# psoc6_01 register map
Vendor: Infineon Technologies; Series: PSOC6_01; File version: 1.0
CPU: CM4 r0p1, little endian, MPU, FPU, VTOR, 3 interrupt priority bits
Registers are 32-bit, read-write, reset 0x0 unless marked. A register's access mark holds for its fields unless they carry their own. Offsets are from the block's base; [hi:lo] are bit positions; lines under a group give offsets from that group.

## BLE (part 2 of 5) — Bluetooth Low Energy Subsystem
Base 0x403C0000
0x1000 BLELL group — Bluetooth Low Energy Link Layer
  0x00 COMMAND_REGISTER wo — Instruction Register
    [7:0] COMMAND
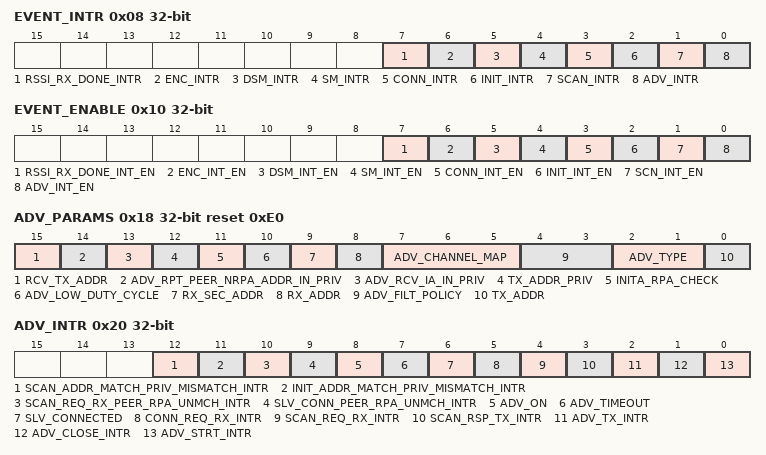
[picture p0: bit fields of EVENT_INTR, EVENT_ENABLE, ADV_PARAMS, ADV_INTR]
  0x08 EVENT_INTR — Event(Interrupt) status and Clear register
    [7] RSSI_RX_DONE_INTR ro — RSSI RX done interrupt.
    [6] ENC_INTR ro — Encryption module interrupt. This interrupt id deprecated and should not be used
    [5] DSM_INTR — Read: Deep sleep mode exit interrupt. This bit is set, when link layer hardware exits from deep sleep mode. Write: Clear deep sleep mode exit interrupt. Write to the register with this bit set to 1, clears the interrupt source.
    [4] SM_INTR — Read: Sleep-mode-exit interrupt. This bit is set, when link layer hardware exits from sleep mode. Write: Clear sleep-mode-exit interrupt. Write to the register with this bit set to 1, clears the interrupt source. This interrupt is deprecated and should not be used.
    [3] CONN_INTR ro — Connection interrupt. If bit is set to 1, it indicates an event occurred in the connection operation. This interrupt is aggregation of interrupts for all the connections. The source of the event for the specific connection, needs to be read from the CONN_INTR register specific to the connection. This bit is cleared, when firmware clears ALL interrupts by writing to the CONN_INTR register.
    [2] INIT_INTR ro — Initiator interrupt. If bit is set to 1, it indicates an event occurred in the initiating procedure. The source of the event needs to be read from the INIT_INTR register. This bit is cleared, when firmware clears ALL interrupts by writing to the INIT_INTR register.
    [1] SCAN_INTR ro — Scanner interrupt. If bit is set to 1, it indicates an event occurred in the scanning procedure. The source of the event needs to be read from the SCAN_INTR register. This bit is cleared, when firmware clears ALL interrupts by writing to the SCAN_INTR register.
    [0] ADV_INTR ro — Advertiser interrupt. If bit is set to 1, it indicates an event occurred in the advertising procedure. The source of the event needs to be read from the ADV_INTR register. This bit is cleared, when firmware clears ALL interrupts by writing to the ADV_INTR register.
  0x10 EVENT_ENABLE — Event indications enable.
    [7] RSSI_RX_DONE_INT_EN — RSSI Rx interrupt enable. 1 - Enable RSSI Rx done interrupt to firmware. 0 - Disable RSSI Rx done interrupt to firmware.
    [6] ENC_INT_EN — Encryption module interrupt enable. 1 - Enable encryption module interrupt to firmware. 0 - disable encryption module interrupt to firmware. This interrupt is deprecated and should not be used
    [5] DSM_INT_EN — Deep Sleep-mode-exit interrupt enable. 1 - enable deep sleep mode exit event to interrupt the firmware. 0 - disable deep sleep mode exit interrupt to firmware.
    [4] SM_INT_EN — Sleep-mode-exit interrupt enable. 1 - enable sleep mode exit event to interrupt the firmware. 0 - disable sleep mode exit interrupt to firmware. This interrupt is deprecated and should not be used.
    [3] CONN_INT_EN — Connection interrupt enable. 1 - enable connection procedure to interrupt the firmware. 0 - disable connection procedure interrupt to firmware.
    [2] INIT_INT_EN — Initiator interrupt enable. 1 - enable initiator procedure to interrupt the firmware. 0 - disable initiator procedure interrupt to firmware.
    [1] SCN_INT_EN — Scanner interrupt enable. 1 - enable scan procedure to interrupt the firmware. 0 - disable scan procedure interrupt to firmware.
    [0] ADV_INT_EN — Advertiser interrupt enable. 1 - enable advertiser procedure to interrupt the firmware. 0 - disable advertiser procedure interrupt to firmware.
  0x18 ADV_PARAMS reset 0xE0 — Advertising parameters register.
    [15] RCV_TX_ADDR ro — Transmit address field of the received packet extracted from the receive packet. This field is used by firmware to report peer_addr_type parameter in the connection complete event.
    [14] ADV_RPT_PEER_NRPA_ADDR_IN_PRIV — Advertiser behavior when a peer Non Resolvable Private Address is received in privacy mode. This bit is valid only if PRIV_1_2 and PRIV_1_2_ADV are set. This is applicable when whitelist is disabled. 1 - Only report the packets with peer NRPA address in privacy mode 0 - Respond to packets with peer NRPA address in privacy mode
    [13] ADV_RCV_IA_IN_PRIV — Advertiser behavior when a peer Identity address is received in privacy mode. This bit is valid only if PRIV_1_2 and PRIV_1_2_ADV are set. 1 - Accept packets with peer identity address not in the Resolving list in privacy mode 0 - Reject packets with peer identity address not in the Resolving list in privacy mode
    [12] TX_ADDR_PRIV — Device own address type subtype when Address type is random. This bit is valid only if PRIV_1_2 and PRIV_1_2_ADV are set. 1 - Random Address type is private. 0 - Random Address type is static.
    [11] INITA_RPA_CHECK — This bit field is used to specify the Advertiser behavior on receiving the same INITA in the connect_req as in the ADV_DIRECT_IND packet it sent. This bit is valid only if PRIV_1_2 and PRIV_1_2_ADV are set. 0 - Accept the connect_req packet 1 - Reject the connect_req packet
    [10] ADV_LOW_DUTY_CYCLE — This bit field is used to specify to the Controller the Low Duty Cycle connectable directed advertising variant being used. 1 - Low Duty Cycle Connectable Directed Advertising. 0 - High Duty Cycle Connectable Directed Advertising.
    [9] RX_SEC_ADDR — Peer secondary addresses type. This is the Direct_Address_type field programmed, only if ADV_DIRECT_IND type is sent. This address type corresponds to the PEER_SERC_ADDR register. Valid only if PRIV_1_2_ADV is set. 1 - Rx secondary addr type is random. 0 - Rx secondary addr type is public
    [8] RX_ADDR — Peer addresses type. This is the Direct_Address_type field programmed, only if ADV_DIRECT_IND type is sent. 1 - Rx addr type is random. 0 - Rx addr type is public
    [7:5] ADV_CHANNEL_MAP — Advertising channel map indicates the advertising channels used for advertising. By setting the bit, corresponding channel is enabled for use. Atleast one channel bit should be set. 7 - enable channel 39. 6 - enable channel 38. 5 - enable channel 37.
    [4:3] ADV_FILT_POLICY — Advertising filter policy. The set of devices that the advertising procedure uses for device filtering is called the White List. 0x0 - Allow scan request from any device, allow connect request from any device. 0x1 - Allow scan request from devices in white list only, allow connect request from any device. 0x2 - Allow scan request from any device, allow connect request from devices in white list only. 0x3 - Allow scan request from devices in white list only, allow connect request from devices in white list only.
    [2:1] ADV_TYPE — The Advertising type is used to determine the packet type that is used for advertising when advertising is enabled. 0x0 - Connectable undirected advertising. (adv_ind) 0x1 - Connectable directed advertising (adv_direct_ind). 0x2 - Discoverable undirected advertising (adv_discover_ind) 0x3 - Non connectable undirected advertising (adv_nonconn_ind).
    [0] TX_ADDR — Device own address type. 1 - Address type is random. 0 - Address type is public.
  0x1C ADV_INTERVAL_TIMEOUT reset 0x20 — Advertising interval register.
    [14:0] ADV_INTERVAL — Range: 0x0020 to 0x4000 (For ADV_IND) 0x00A0 to 0x4000 (For ADV_SCAN_IND and NONCONN_IND) Invalid for ADV_DIRECT_IND Time = N * 0.625 msec Time Range: 20 ms to 10.24 sec. For directed advertising, firmware programs the default value of 1.28 seconds. In MMMS mode, this register is used as ADV_NI_TIMER when the ADV_NI_VALID is set by firmware
  0x20 ADV_INTR — Advertising interrupt status and Clear register
    [12] SCAN_ADDR_MATCH_PRIV_MISMATCH_INTR — If this bit is set it indicates that an Identity address is received from an initiator and matches an entry in the resolving list, but peer IRK is set and hence a corresponding RPA is expected from the initiator Write to the register with this bit set to 1, clears the interrupt source. This bit is valid only if PRIV_1_2 and PRIV_1_2_ADV are set.
    [11] INIT_ADDR_MATCH_PRIV_MISMATCH_INTR — If this bit is set it indicates that an Identity address is received from a Scanner and matches an entry in the resolving list, but peer IRK is set and hence a corresponding RPA is expected from the Scanner Write to the register with this bit set to 1, clears the interrupt source. This bit is valid only if PRIV_1_2 and PRIV_1_2_ADV are set.
    [10] SCAN_REQ_RX_PEER_RPA_UNMCH_INTR — If this bit is set it indicates scan request packet received, but the peer device Resolvable Private Address is not resolved/ ID or NRPA are not matched yet. Write to the register with this bit set to 1, clears the interrupt source. This bit is valid only if PRIV_1_2 and PRIV_1_2_ADV are set.
    [9] SLV_CONN_PEER_RPA_UNMCH_INTR — If this bit is set it indicates that connection is created as slave, but the peer device Resolvable Private Address is not resolved/ ID or NRPA are not matched yet. If the address is not resolved prior to connection establishment, the connection will be terminated. Write to the register with this bit set to 1, clears the interrupt source. This bit is valid only if PRIV_1_2 and PRIV_1_2_ADV are set.
    [8] ADV_ON ro — Advertiser procedure is ON in hardware. Indicates that advertiser procedure is ON in hardware. 1 - ON 0 - OFF
    [7] ADV_TIMEOUT — If this bit is set it indicates that the directed advertising event has timed out after 1.28 seconds. Applicable in adv_direct_ind advertising. Write to the register with this bit set to 1, clears the interrupt source.
    [6] SLV_CONNECTED — If this bit is set it indicates that connection is created as slave. Write to the register with this bit set to 1, clears the interrupt source. Note: On a slave connection creation, the link layer cannot enter deepsleep mode in the same slot . It can enter deepsleep mode only in the subsequent slots.
    [5] CONN_REQ_RX_INTR — If this bit is set it indicates connect request packet is received. Write to the register with this bit set to 1, clears the interrupt source.
    [4] SCAN_REQ_RX_INTR — If this bit is set it indicates scan request packet received. Write to the register with this bit set to 1, clears the interrupt source.
    [3] SCAN_RSP_TX_INTR — If this bit is set it indicates scan response packet transmitted in response to previous scan request packet received. Write to the register with this bit set to 1, clears the interrupt source.
    [2] ADV_TX_INTR — If this bit is set it indicates ADV packet is transmitted. Write to the register with this bit set to 1, clears the interrupt source.
    [1] ADV_CLOSE_INTR — If this bit is set it indicates current advertising event is closed. Write to the register with this bit set to 1, clears the interrupt source.
    [0] ADV_STRT_INTR — If this bit is set it indicates a new advertising event started after interval expiry. Write to the register with this bit set to 1, clears the interrupt source.
  0x24 ADV_NEXT_INSTANT ro — Advertising next instant.
    [15:0] ADV_NEXT_INSTANT — Shows the next start of advertising event with reference to the internal reference clock.
  0x28 SCAN_INTERVAL reset 0x10
    [15:0] SCAN_INTERVAL — Scan interval register. Interval between two consecutive scanning events. Firmware sets the scanning interval value to this register before issuing start scan command. Range: 0x0004 to 0x4000 Default: 0x0010 (10 ms) Time = N * 0.625 msec Time Range: 2.5 msec to 10.24 sec. In MMMS mode, this register is used as SCAN_NI_TIMER when the SCAN_NI_VALID is set by firmware
  0x2C SCAN_WINDOW reset 0x10
    [15:0] SCAN_WINDOW — Duration of scan in a scanning event, which should be less than or equal to scan interval value. Firmware sets the scan window value to this register before issuing start scan command. Range: 0x0004 to 0x4000 Default: 0x0010 (10 ms) Time = N * 0.625 msec Time Range: 2.5 msec to 10.24 sec. (To prevent ADV RX - SCAN REQ TX - SCAN RSP RX spilling over across the scan window, when not in continuous scan, the scan window must be 2 slots less that the scan interval.
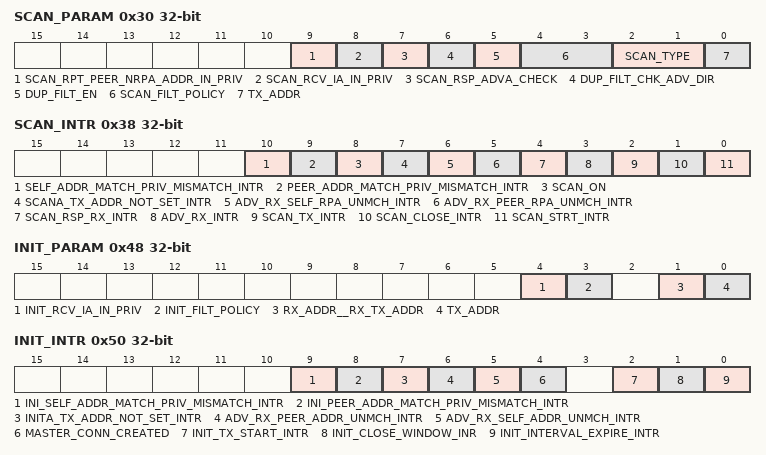
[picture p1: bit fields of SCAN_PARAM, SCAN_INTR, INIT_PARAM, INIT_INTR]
  0x30 SCAN_PARAM — Scanning parameters register
    [9] SCAN_RPT_PEER_NRPA_ADDR_IN_PRIV — Scanner behavior when a peer Non Resolvable Private Address is received in privacy mode. This bit is valid only if PRIV_1_2 and PRIV_1_2_SCAN are set. This is applicable when whitelist is disabled. 1 - Only report packets with peer NRPA address in privacy mode 0 - Respond packets with peer NRPA address in privacy mode
    [8] SCAN_RCV_IA_IN_PRIV — Scanner behavior when a peer Identity address is received in privacy mode. This bit is valid only if PRIV_1_2 and PRIV_1_2_SCAN are set. 1 - Accept packets with peer identity address not in the Resolving list in privacy mode 0 - Reject packets with peer identity address not in the Resolving list in privacy mode
    [7] SCAN_RSP_ADVA_CHECK — This bit field is used to specify the Scanner behavior with respect to ADVA while receiving a SCAN_RSP packet. This bit is valid only if PRIV_1_2 and PRIV_1_2_SCAN are set. 0 - The ADVA in SCAN_RSP packets are not verified 1 - The ADVA in SCAN_RSP packets are verified against ADVA received in ADV packet . If it fails, then abort the packet.
    [6] DUP_FILT_CHK_ADV_DIR — This bit field is used to specify the Scanner duplicate filter behavior for ADV_DIRECT_IND packet when duplicate DUP_FILT_EN is set. This bit is valid only if PRIV_1_2 and PRIV_1_2_SCAN are set. 0 - Do not filter ADV_DIRECT_IND duplicate packets. 1 - Filter ADV_DIRECT_IND duplicate packets
    [5] DUP_FILT_EN — Filter duplicate packets. 1- Duplicate filtering enabled. 0- Duplicate filtering not enabled. This field is derived from the LE_set_scan_enable command.
    [4:3] SCAN_FILT_POLICY — The scanner filter policy determines how the scanner processes advertising packets. 0x00 - Accept advertising packets from any device. 0x01 - Accept advertising packets from only devices in the whitelist. In the above 2 policies, the directed advertising packets which are not addressed to this device are ignored. 0x10 - Accept all undirected advertising packets and directed advertising packet addressed to this device. 0x11 - Accept undirected advertising packets from devices in the whitelist and directed advertising packet addressed to this device In the above 2 policies, the directed advertising packets where the initiator address is a resolvable private address are accepted. The above 2 policies are extended scanner filter policies.
    [2:1] SCAN_TYPE — 0x00 - passive scanning.(default) 0x01 - active scanning. 0x10 - RFU 0x11 - RFU
    [0] TX_ADDR — Device's own address type. 1 - addr type is random. 0 - addr type is public.
  0x38 SCAN_INTR — Scan interrupt status and Clear register
    [10] SELF_ADDR_MATCH_PRIV_MISMATCH_INTR — If this bit is set it indicates that the self Identity address is received from an initiator and matches, but self IRK is set and hence a corresponding RPA is expected from the initiator Write to the register with this bit set to 1, clears the interrupt source. This bit is valid only if PRIV_1_2 and PRIV_1_2_SCAN are set.
    [9] PEER_ADDR_MATCH_PRIV_MISMATCH_INTR — If this bit is set it indicates that an Identity address is received from an initiator and matches an entry in the resolving list, but peer IRK is set and hence a corresponding RPA is expected from the initiator Write to the register with this bit set to 1, clears the interrupt source. This bit is valid only if PRIV_1_2 and PRIV_1_2_SCAN are set.
    [8] SCAN_ON ro — Scan procedure status. 1 - scan procedure is active. 0 - scan procedure is not active.
    [7] SCANA_TX_ADDR_NOT_SET_INTR — If this bit is set it indicates that a valid ScanA RPA to be transmitted in SCAN_REQ packet in response to an ADV packet is not present in the resolving list Write to the register with this bit set to 1, clears the interrupt source. This bit is valid only if PRIV_1_2 and PRIV_1_2_SCAN are set.
    [6] ADV_RX_SELF_RPA_UNMCH_INTR — If this bit is set it indicates ADV_DIRECT packet received but the self device Resolvable Private Address is not resolved yet. Firmware can read the content of the packet from the INIT_SCN_ADV_RX_FIFO. This bit is valid only if PRIV_1_2 and PRIV_1_2_SCAN are set. Write to the register with this bit set to 1, clears the interrupt source. This interrupt is generated while active/passive scanning upon receiving adv_direct packets.
    [5] ADV_RX_PEER_RPA_UNMCH_INTR — If this bit is set it indicates ADV packet received but the peer device Address is not match yet. Firmware can read the content of the packet from the INIT_SCN_ADV_RX_FIFO. This bit is valid only if PRIV_1_2 and PRIV_1_2_SCAN are set. Write to the register with this bit set to 1, clears the interrupt source. This interrupt is generated while active/passive scanning upon receiving adv packets.
    [4] SCAN_RSP_RX_INTR — If this bit is set it indicates SCAN_RSP packet is received. Firmware can read the content of the packet from the INIT_SCN_ADV_RX_FIFO. Write to the register with this bit set to 1, clears the interrupt source. NOTE: This interrupt is generated while active scanning upon receiving scan response packet.
    [3] ADV_RX_INTR — If this bit is set it indicates ADV packet received. Firmware can read the content of the packet from the INIT_SCN_ADV_RX_FIFO. Write to the register with this bit set to 1, clears the interrupt source. This interrupt is generated while active/passive scanning upon receiving adv packets. Note: Any ADV RX interrupt received after issuing SCAN_STOP command must be ignored and the ADVCH FIFO flushed.
    [2] SCAN_TX_INTR — If this bit is set it indicates scan request packet is transmitted. Write to the register with this bit set to 1, clears the interrupt source.
    [1] SCAN_CLOSE_INTR — If this bit is set it indicates scan window is closed. Write to the register with this bit set to 1, clears the interrupt source.
    [0] SCAN_STRT_INTR — If this bit is set it indicates scan window is opened. Write to the register with this bit set to 1, clears the interrupt source.
  0x3C SCAN_NEXT_INSTANT ro — Advertising next instant.
    [15:0] NEXT_SCAN_INSTANT — Shows the instant with respect to internal reference clock of resolution 625 us at which next scanning event begins.
  0x40 INIT_INTERVAL — Initiator Interval Register
    [15:0] INIT_SCAN_INTERVAL — Initiator interval register. Firmware sets the initiator's scanning interval value to this regis-ter before issuing create connection command. Interval between two consecutive scanning events. Range: 0x0004 to 0x4000 Time = N * 0.625 msec Time Range: 2.5 msec to 10.24 sec. In MMMS mode, this register is used as INIT_NI_TIMER when the INIT_NI_VALID is set by firmware
  0x44 INIT_WINDOW — Initiator window Register
    [15:0] INIT_SCAN_WINDOW — Duration of scan in a scanning event, which should be less than or equal to scan interval value. Firmware sets the scan window value to this register before issuing create connection command. Range: 0x0004 to 0x4000 Time = N * 0.625 msec Time Range: 2.5 msec to 10.24 sec. In MMMS mode, this register is used as INIT_NI_TIMER when the INIT_NI_VALID is set by firmware
  0x48 INIT_PARAM — Initiator parameters register
    [4] INIT_RCV_IA_IN_PRIV — Init behavior when a peer Identity address is received in privacy mode. This bit is valid only if PRIV_1_2 and PRIV_1_2_INIT are set. 1 - Accept packets with peer identity address not in the Resolving list in privacy mode 0 - Reject packets with peer identity address not in the Resolving list in privacy mode & HW_RSLV_LIST_FULL is not set
    [3] INIT_FILT_POLICY — The Initiator_Filter_Policy is used to determine whether the White List is used or not. 0 - White list is not used to determine which advertiser to connect to. Instead the Peer_Address_Type and Peer Address fields are used to specify the address type and address of the advertising device to connect to. 1 - White list is used to determine the advertising device to connect to. Peer_Address_Type and Peer_Address fields are ignored when whitelist is used.
    [1] RX_ADDR__RX_TX_ADDR — Peer address type. The rx_addr field is updated by the receiver with the address type of the received connectable advertising packet. 1 - addr type is random. 0 - addr type is public.
    [0] TX_ADDR — Device' own address type. 1 - addr type is random. 0 - addr type is public.
  0x50 INIT_INTR — Scan interrupt status and Clear register
    [9] INI_SELF_ADDR_MATCH_PRIV_MISMATCH_INTR — If this bit is set it indicates that - an Identity address is received from an initiator and matches an entry in the resolving list, but peer IRK is set and hence a corresponding RPA is expected from the initiator - or an RPA is received from an initiator and matches an entry in the resolving list, but peer IRK is not set and hence a corresponding Identity address is expected from the initiator Write to the register with this bit set to 1, clears the interrupt source. This bit is valid only if PRIV_1_2 and PRIV_1_2_INIT are set.
    [8] INI_PEER_ADDR_MATCH_PRIV_MISMATCH_INTR — If this bit is set it indicates that an Identity address is received from an initiator and matches an entry in the resolving list, but peer IRK is set and hence a corresponding RPA is expected from the initiator Write to the register with this bit set to 1, clears the interrupt source. This bit is valid only if PRIV_1_2 and PRIV_1_2_INIT are set.
    [7] INITA_TX_ADDR_NOT_SET_INTR — If this bit is set it indicates that a valid INITA RPA to be transmitted in CONN_REQ packet in response to an ADV packet is not present in the resolving list Write to the register with this bit set to 1, clears the interrupt source. This bit is valid only if PRIV_1_2 and PRIV_1_2_INIT are set.
    [6] ADV_RX_PEER_ADDR_UNMCH_INTR — If this bit is set it indicates ADV packet received but the peer device Address is not matched yet. Firmware can read the content of the packet from the INIT_SCN_ADV_RX_FIFO. This bit is valid only if PRIV_1_2 and PRIV_1_2_INIT are set. Write to the register with this bit set to 1, clears the interrupt source. This interrupt is generated while active/passive scanning upon receiving adv packets.
    [5] ADV_RX_SELF_ADDR_UNMCH_INTR — If this bit is set it indicates ADV_DIRECT packet received but the self device Resolvable Private Address is not resolved yet. Firmware can read the content of the packet from the INIT_SCN_ADV_RX_FIFO. This bit is valid only if PRIV_1_2 and PRIV_1_2_INIT are set. Write to the register with this bit set to 1, clears the interrupt source. This interrupt is generated while active/passive scanning upon receiving adv packets.
    [4] MASTER_CONN_CREATED — If this bit is set it indicates connection is created as master. Write to the register with this bit set to 1, clears the interrupt source.
    [2] INIT_TX_START_INTR — If this bit is set it indicates initiator packet (CONREQ) transmission has started. Write to the register with this bit set to 1, clears the interrupt source.
    [1] INIT_CLOSE_WINDOW_INR — If this bit is set it indicates initiator scan window has finished. Write to the register with this bit set to 1, clears the interrupt source.
    [0] INIT_INTERVAL_EXPIRE_INTR — If this bit is set it indicates initiator scan window has started. Write to the register with this bit set to 1, clears the interrupt source.
  0x54 INIT_NEXT_INSTANT ro — Initiator next instant.
    [15:0] INIT_NEXT_INSTANT — Shows the instant with respect to internal reference clock of resolution 625 us at which next initiator scanning event begins.
  0x58 DEVICE_RAND_ADDR_L — Lower 16 bit random address of the device.
    [15:0] DEVICE_RAND_ADDR_L — Lower 16 bit of 48-bit random address of the device.
  0x5C DEVICE_RAND_ADDR_M — Middle 16 bit random address of the device.
    [15:0] DEVICE_RAND_ADDR_M — Middle 16 bit of 48-bit random address of the device.
  0x60 DEVICE_RAND_ADDR_H — Higher 16 bit random address of the device.
    [15:0] DEVICE_RAND_ADDR_H — Higher 16 bit of 48-bit random address of the device.
  0x68 PEER_ADDR_L — Lower 16 bit address of the peer device.
    [15:0] PEER_ADDR_L — Lower 16 bit of 48-bit address of the peer device.
  0x6C PEER_ADDR_M — Middle 16 bit address of the peer device.
    [15:0] PEER_ADDR_M — Middle 16 bit of 48-bit address of the peer device.
  0x70 PEER_ADDR_H — Higher 16 bit address of the peer device.
    [15:0] PEER_ADDR_H — Higher 16 bit of 48-bit address of the peer device. The peer address registers are used for multiple purposes. The register is written by firmware to provide the peer address to be used for a hardware procedure. When firmware reads the register, it reads back peer address values updated by hardware. While doing directed Advertising, the firmware writes the peer address of the device specified by the Di-rect_Address parameter of the LE_Set_Advertising_Parameters command. In non MMMS mode, While device is configured as an initiator without white list filtering, the peer address specified in the peer_address field of the create connection command is programmed into this register, which is used by hard-ware procedures. In non MMMS mode, While device is configured as an initiator and white list is enabled, firmware can read this register to get the address of the peer device from which connectable ADV packet was received and to which the connection is created. When a connection is created as a slave, the firmware can read this register to get the address of the peer de-vice to which connection is created.
  0x78 WL_ADDR_TYPE — whitelist address type
    [15:0] WL_ADDR_TYPE — 8 address type bits corresponding to the device address stored. 1 - Address type is random. 0 - Address type is public.
  0x7C WL_ENABLE — whitelist valid entry bit
    [15:0] WL_ENABLE — Stores the valid entry bit corresponding to each of the eight device address stored in the whitelist. 1 - White list entry is Valid 0 - White list entry is Invalid
  0x80 TRANSMIT_WINDOW_OFFSET
    [15:0] TX_WINDOW_OFFSET — This is used to determine the first anchor point for the master transmission, from the time of connection creation. Range: This shall be a multiple of 1.25 ms in the range of 0 ms to connInterval value.
  0x84 TRANSMIT_WINDOW_SIZE
    [7:0] TX_WINDOW_SIZE — window_size along with the window_offset is used to calculate the first connection point anchor point for the master. This shall be a multiple of 1.25 ms in the range of 1.25 ms to the lesser of 10 ms and (connInterval - 1.25 ms). Values range from 0 to 10 ms.
  0x88 DATA_CHANNELS_L0 — Data channel map 0 (lower word)
    [15:0] DATA_CHANNELS_L0 — This register field indicates which of the data channels are in use. This stores the information for the lower 16 (15:0) data channel indices. '1' indicates the corresponding data channel is used and '0' indicates the channel is unused.
  0x8C DATA_CHANNELS_M0 — Data channel map 0 (middle word)
    [15:0] DATA_CHANNELS_M0 — This register field indicates which of the data channels are in use. This stores the information for the middle 16 (32:16) data channel indices. '1' indicates the corresponding data channel is used and '0' indicates the channel is unused.
  0x90 DATA_CHANNELS_H0 — Data channel map 0 (upper word)
    [4:0] DATA_CHANNELS_H0 — This register field indicates which of the data channels are in use. This stores the information for the upper 5 (36:32) data channel indices. '1' indicates the corresponding data channel is used and '0' indicates the channel is unused. Note: The Data channel map 0 and data channel map 1 are two sets of channel maps stored, common for all the connections. At any given time, only two maps can be maintained and the connections will use one of the two sets as indicated by the channel map index field in the CE_CNFG_STS registers specific to the link. Firmware must also manage to update this field along with the map.
  0x98 DATA_CHANNELS_L1 — Data channel map 1 (lower word)
    [15:0] DATA_CHANNELS_L1 — This register field indicates which of the data channels are in use. This stores the information for the lower 16 (15:0) data channel indices. '1' indicates the corresponding data channel is used and '0' indicates the channel is unused.
  0x9C DATA_CHANNELS_M1 — Data channel map 1 (middle word)
    [15:0] DATA_CHANNELS_M1 — This register field indicates which of the data channels are in use. This stores the information for the middle 16 (32:16) data channel indices. '1' indicates the corresponding data channel is used and '0' indicates the channel is unused.
  0xA0 DATA_CHANNELS_H1 — Data channel map 1 (upper word)
    [4:0] DATA_CHANNELS_H1 — This register field indicates which of the data channels are in use. This stores the information for the upper 5 data channel indices. '1' indicates the corresponding data channel is used and '0' indicates the channel is unused. Note: The Data channel map 0 and data channel map 1 are two sets of channel maps stored, common for all the connections. At any given time, only two maps can be maintained and the connections will use one of the two sets as indicated by the channel map index field in the CE_CNFG_STS registers specific to the link. Firmware must also manage to update this field along with the map.
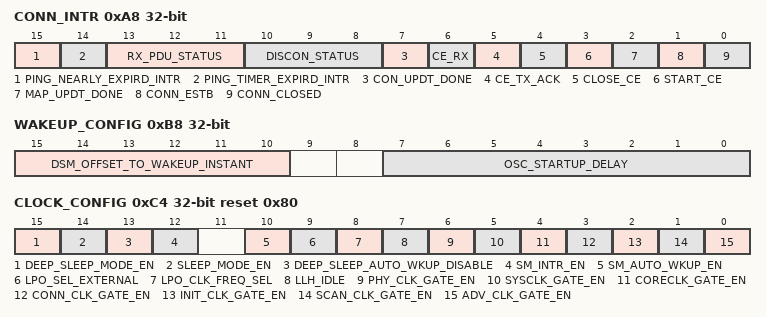
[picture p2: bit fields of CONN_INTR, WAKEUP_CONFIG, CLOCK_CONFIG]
  0xA8 CONN_INTR — Connection interrupt status and Clear register
    [15] PING_NEARLY_EXPIRD_INTR — If this is set, it indicates that ping timer has nearly expired. If this bit is written with 1, it clears the interrupt.
    [14] PING_TIMER_EXPIRD_INTR — If this is set, it indicates that ping timer has expired. If this bit is written with 1, it clears the interrupt.
    [13:11] RX_PDU_STATUS ro — Status of PDU received. This information is valid along with receive interrupt. xx1 - Bad Packet (packet with CRC error) 000 - empty PDU 010 - new data (non-empty) PDU 110 - Duplicate Packet
    [10:8] DISCON_STATUS ro — Reason for disconnect - indicates the reason the link is disconnected by hardware. 001 - connection failed to be established 010 - supervision timeout 011 - kill connection by host 100 - kill connection after ACK transmitted 101 - PDU response timer expired
    [7] CON_UPDT_DONE — This bit is set when the last connection event with previous connec-tion parameters is reached. The bit is set immediately after the re-ceive operation at the anchor point of the last connection event. If this bit is written with 1, it clears the connection updated interrupt.
    [6] CE_RX — If this bit is set it indicates that a packet is received in the connection event. If this bit is written with 1, it clears the connection event received interrupt.
    [5] CE_TX_ACK — If this bit is set it indicates that the connection event transmission acknowledgement is received for the previous non-empty packet transmitted. If this bit is written with 1, it clears the ce transmission acknowledgement interrupt.
    [4] CLOSE_CE — If this bit is set it indicates that the connection event closed interrupt has happened. If this bit is written with 1, it clears the connection event closed interrupt.
    [3] START_CE — If this bit is set it indicates that the connection event started interrupt has happened. If this bit is written with 1, it clears the connection event started interrupt.
    [2] MAP_UPDT_DONE — If this bit is set it indicates that the channel map update is completed at the instant specified by the firmware. If this bit is written with 1, it clears the map update done interrupt.
    [1] CONN_ESTB — If this bit is set it indicates that the connection has been established. The bit is also set when a connection update procedure is complet-ed, at the start of the first anchor point with the updated parameters. If this bit is written with 1, it clears the connection established interrupt.
    [0] CONN_CLOSED — If this bit is set it indicates that the link is disconnected. If this bit is written with 1, it clears the connection updated interrupt.
  0xAC CONN_STATUS ro — Connection channel status
    [15:12] RECEIVE_PACKET_COUNT — This field stores the count for the number of receive packets in the receive FIFO that are still not ready by firmware. The counter value is incremented by hardware for every good packet it stores in the FIFO. After firmware reads a packet, it decrements the counter by issuing the PACKET_RECEIVED command from the commander.
  0xB0 CONN_INDEX — Connection Index register
    [15:0] CONN_INDEX — This field is used to index the multiple connections existing. Range is 0 to maximum number of connections supported. For a single connection device, conn_index is 0.
  0xB8 WAKEUP_CONFIG — Wakeup configuration
    [15:10] DSM_OFFSET_TO_WAKEUP_INSTANT — Number of 'slots' before the wake up instant before which the hardware needs to exit from deep sleep mode. The slot is of 0.625ms period. This is a onetime configuration field, which is used every time hardware does an auto-wakeup before the next wakeup instant.
    [7:0] OSC_STARTUP_DELAY — Oscillator stabilization/startup delay. This is in X.Y for-mat where X is in terms of number of BT slots (625 us) and Y is in terms of number of clock periods of 16KHz clock input, required for RF oscillator to stabilize the clock output to the controller on its output pin, after oscillator is turned ON. In this period the clock is as-sumed to be unstable, and so the controller does not turn on the clock to internal logic till this period is over. This means, the wake up from deep sleep mode must account for this delay before the wakeup instant. Osc_startup_delay[7:5] is number of slots(625us) Osc_startup_delay[4:0 is number of clock periods of 16KHz clock (Warning: Min. value of Osc_startup_delay [4:0] sup-ported is 1 and Max. value is 9. Therefore programma-ble range is 1 to 9)
  0xC0 WAKEUP_CONTROL
    [15:0] WAKEUP_INSTANT — Instant, with reference to the internal 16-bit clock reference, at which the hardware must wakeup from deep sleep mode. This is calculated by firmware based on the next closest instant where a controller operation is required (like advertiser/scanner). Firmware reads the next instant of the procedures in the corresponding *_NEXT_INSTANT registers. This value is used only when hardware auto wakeup from deep sleep mode is enabled in the clock control register. Note: it is recommended to program wakeup_instant such a way that the actual instant to wakeup shall be at least two counts (two slots of 625 us) ahead of reference clock when entering DSM. The actual instant to wakeup is 'wakeup_instant - dsm_offset_to_wakeup_instant - osc_startup_delay, and it shall be greater than 'reference clock + 2'
  0xC4 CLOCK_CONFIG reset 0x80 — Clock control
    [15] DEEP_SLEEP_MODE_EN — Enable deep sleep mode. 1 - enable, 0 - disable. Enables hardware logic related to deep sleep mode to control the deep sleep mode operation. If disabled, the related logic is not executed and hardware cannot enter deep sleep mode.
    [14] SLEEP_MODE_EN — Enable sleep mode. 1 - enable, 0 - disable. Enables hardware to control sleep mode operation. This feature is not available. FW should never set this bit
    [13] DEEP_SLEEP_AUTO_WKUP_DISABLE — Disable Auto Wakeup in DEEP_SLEEP mode. 1 - Disable Auto Wakeup 0 - Auto Wakeup enabled
    [12] SM_INTR_EN — Enable SM exit interrupt. 1 - enable, 0 - disable. Enables hardware to generate an interrupt while exiting sleep mode - irrespective of whether it is initiated by hardware or firmware. The interrupt is captured and stored till it gets cleared. Disabling this bit mask the sleep mode exit event from hardware & firmware. This feature is not available. FW should never set this bit
    [10] SM_AUTO_WKUP_EN — Enable sleep mode auto wakeup enable. 1- enable, 0 - disable. Enables hardware to automatically wakeup from sleep mode at the instant = wakeup_instant - sm_offset_to_wakeup_instant. The wakeup_insant is the field in the wakeup control register described earlier. The sm_offset_to_wakeup_instant value is the field described in the wakeup configuration register.
    [9] LPO_SEL_EXTERNAL — Select external sleep clock. 1 - External clock, 0 - inter-nal generated clock. The field is used to select either the low power clock in-put on sleep_clk input pin(of frequency 16.384KHz) di-rectly to run the DSM logic or to use the internal gener-ated reference clock(of 16KHz) for the same.
    [8] LPO_CLK_FREQ_SEL — Clock frequency select. 0 - 32KHz, 1 - 32.768KHz. Base frequency of the sleep_clk input used for generat-ing the internal reference clock of approximate 16Khz frequency.
    [7] LLH_IDLE ro — Indicates if hardware is doing any transmit/receive operation. This information is used by firmware to decide to program the hardware into deep sleep mode. 1 - LL hardware is idle. 0 - LL hardware is busy. In this case LL hardware will not enter deep sleep mode, even if firmware gives an enter DSM command. (In this situation hardware generates dsm exit interrupt to inform firmware that DSM entry was not successful).
    [6] PHY_CLK_GATE_EN — Digital PHY clock enable. 1- enable, 0-disable. Enable the Digital PHY to shutdown the clock. When 1, it indicates that controller has an upcoming activity so PHY clock must be turned ON. When 0, it indicates inactivity in the controller.
    [5] SYSCLK_GATE_EN — Sysclk gate enable. 1- enable, 0 - disable. Enables clock gating of system clock input to the link layer. If 1, it enables the DSM logic to control the clock gate for system clock input from pin. If 0, the DSM logic has no control and the system clock is always ON.
    [4] CORECLK_GATE_EN — Core clock gate enable. 1 - enable, 0 - disable. Enables gating of clock to the llh_core module in hard-ware. If 1, the sleep mode/deep sleep mode logic can control the clock gate to shutdown/wakeup the clock to the module. If 0, the logic has no control and clock is always turned ON.
    [3] CONN_CLK_GATE_EN — Connection block clock gate enable. 1 - enable, 0 - disable. Enables gating of clock to the connection module (llh_connch_top) in hardware. If 1, the sleep mode logic can control the clock gate to shutdown/wakeup the clock to the engine. If 0, the logic has no control and clock to the module is always turned ON.
    [2] INIT_CLK_GATE_EN — Initiator block clock gate enable. 1 - enable, 0 - disable. Enables gating of clock to the initiator module (llh_init). If 1, the sleep mode logic can control the clock gate to shutdown/wakeup the clock to the module. If 0, the logic has no control and clock to the module is always turned ON.
    [1] SCAN_CLK_GATE_EN — Scan block clock gate enable. 1 - enable, 0 - disable. Enables gating of clock to the scanner module (llh_scan) in hardware. If 1, the sleep mode logic can control the clock gate to shutdown/wakeup the clock to the module. If 0, the logic has no control and clock to the module is always turned ON.
    [0] ADV_CLK_GATE_EN — Advertiser block clock gate enable. 1 - enable, 0 - disable. Enables gating of clock to the advertiser module (llh_adv) in hardware. If 1, the sleep mode logic can control the clock gate to shutdown/wakeup the clock to the module. If 0, the logic has no control and clock to the module is always turned ON.
